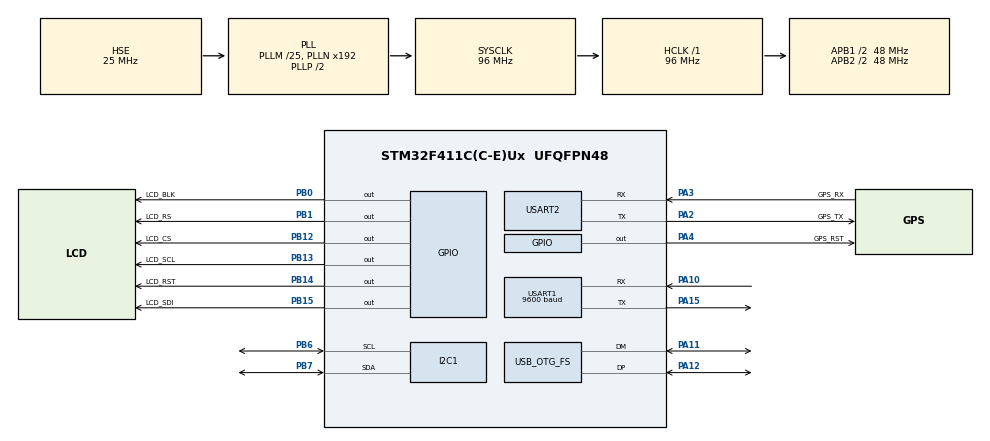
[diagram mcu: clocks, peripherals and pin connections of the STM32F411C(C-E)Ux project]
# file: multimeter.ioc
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Dma.I2C1_RX.0.Direction=DMA_PERIPH_TO_MEMORY
Dma.I2C1_RX.0.FIFOMode=DMA_FIFOMODE_DISABLE
Dma.I2C1_RX.0.Instance=DMA1_Stream0
Dma.I2C1_RX.0.MemDataAlignment=DMA_MDATAALIGN_BYTE
Dma.I2C1_RX.0.MemInc=DMA_MINC_ENABLE
Dma.I2C1_RX.0.Mode=DMA_NORMAL
Dma.I2C1_RX.0.PeriphDataAlignment=DMA_PDATAALIGN_BYTE
Dma.I2C1_RX.0.PeriphInc=DMA_PINC_DISABLE
Dma.I2C1_RX.0.Priority=DMA_PRIORITY_LOW
Dma.I2C1_TX.1.Direction=DMA_MEMORY_TO_PERIPH
Dma.I2C1_TX.1.FIFOMode=DMA_FIFOMODE_DISABLE
Dma.I2C1_TX.1.Instance=DMA1_Stream1
Dma.I2C1_TX.1.MemDataAlignment=DMA_MDATAALIGN_BYTE
Dma.I2C1_TX.1.MemInc=DMA_MINC_ENABLE
Dma.I2C1_TX.1.Mode=DMA_NORMAL
Dma.I2C1_TX.1.PeriphDataAlignment=DMA_PDATAALIGN_BYTE
Dma.I2C1_TX.1.PeriphInc=DMA_PINC_DISABLE
Dma.I2C1_TX.1.Priority=DMA_PRIORITY_LOW
Dma.Request0=I2C1_RX
Dma.Request1=I2C1_TX
Mcu.Family=STM32F4
Mcu.Name=STM32F411C(C-E)Ux
Mcu.Package=UFQFPN48
NVIC.DMA1_Stream0_IRQn=true\:0\:0\:false\:false\:true\:false\:true\:true
NVIC.DMA1_Stream1_IRQn=true\:0\:0\:false\:false\:true\:false\:true\:true
NVIC.I2C1_ER_IRQn=true\:0\:0\:false\:false\:true\:true\:true\:true
NVIC.I2C1_EV_IRQn=true\:0\:0\:false\:false\:true\:true\:true\:true
NVIC.OTG_FS_IRQn=true\:0\:0\:false\:false\:true\:false\:true\:true
NVIC.PriorityGroup=NVIC_PRIORITYGROUP_4
NVIC.USART1_IRQn=true\:0\:0\:true\:false\:true\:true\:true\:true
PA10.GPIO_PuPd=GPIO_PULLUP
PA10.Mode=Asynchronous
PA10.Signal=USART1_RX
PA11.Mode=Device_Only
PA11.Signal=USB_OTG_FS_DM
PA12.Mode=Device_Only
PA12.Signal=USB_OTG_FS_DP
PA13.Mode=Serial_Wire
PA13.Signal=SYS_JTMS-SWDIO
PA14.Mode=Serial_Wire
PA14.Signal=SYS_JTCK-SWCLK
PA15.GPIO_PuPd=GPIO_PULLUP
PA15.Mode=Asynchronous
PA15.Signal=USART1_TX
PA2.GPIO_Label=GPS_TX
PA2.Mode=Asynchronous
PA2.Signal=USART2_TX
PA3.GPIO_Label=GPS_RX
PA3.Mode=Asynchronous
PA3.Signal=USART2_RX
PA4.GPIO_Label=GPS_RST
PA4.Signal=GPIO_Output
PB0.GPIO_Label=LCD_BLK
PB0.GPIO_PuPd=GPIO_PULLUP
PB0.Signal=GPIO_Output
PB1.GPIO_Label=LCD_RS
PB1.GPIO_PuPd=GPIO_PULLUP
PB1.Signal=GPIO_Output
PB12.GPIO_Label=LCD_CS
PB12.GPIO_PuPd=GPIO_PULLUP
PB12.Signal=GPIO_Output
PB13.GPIO_Label=LCD_SCL
PB13.GPIO_PuPd=GPIO_PULLUP
PB13.Signal=GPIO_Output
PB14.GPIO_Label=LCD_RST
PB14.GPIO_PuPd=GPIO_PULLUP
PB14.Signal=GPIO_Output
PB15.GPIO_Label=LCD_SDI
PB15.GPIO_PuPd=GPIO_PULLUP
PB15.Signal=GPIO_Output
PB6.Mode=I2C
PB6.Signal=I2C1_SCL
PB7.Mode=I2C
PB7.Signal=I2C1_SDA
PC14-OSC32_IN.Mode=LSE-External-Oscillator
PC14-OSC32_IN.Signal=RCC_OSC32_IN
PC15-OSC32_OUT.Mode=LSE-External-Oscillator
PC15-OSC32_OUT.Signal=RCC_OSC32_OUT
PH0\ -\ OSC_IN.Mode=HSE-External-Oscillator
PH0\ -\ OSC_IN.Signal=RCC_OSC_IN
PH1\ -\ OSC_OUT.Mode=HSE-External-Oscillator
PH1\ -\ OSC_OUT.Signal=RCC_OSC_OUT
ProjectManager.HeapSize=0x200
ProjectManager.StackSize=0x400
ProjectManager.TargetToolchain=STM32CubeIDE
RCC.48MHZClocksFreq_Value=48000000
RCC.AHBFreq_Value=96000000
RCC.APB1CLKDivider=RCC_HCLK_DIV2
RCC.APB1Freq_Value=48000000
RCC.APB1TimFreq_Value=96000000
RCC.APB2CLKDivider=RCC_HCLK_DIV2
RCC.APB2Freq_Value=48000000
RCC.APB2TimFreq_Value=96000000
RCC.CortexFreq_Value=96000000
RCC.HCLKFreq_Value=96000000
RCC.HSE_VALUE=25000000
RCC.HSI_VALUE=16000000
RCC.PLLM=25
RCC.SYSCLKFreq_VALUE=96000000
RCC.SYSCLKSource=RCC_SYSCLKSOURCE_PLLCLK
RCC.VCOOutputFreq_Value=192000000
TIM5.Prescaler=95
USART1.BaudRate=9600
USART1.VirtualMode=VM_ASYNC
USART2.VirtualMode=VM_ASYNC
USB_DEVICE.CLASS_NAME_FS=CDC
USB_DEVICE.VirtualMode=Cdc
USB_DEVICE.VirtualModeFS=Cdc_FS
USB_OTG_FS.VirtualMode=Device_Only
VP_TIM5_VS_ClockSourceINT.Mode=Internal
VP_USB_DEVICE_VS_USB_DEVICE_CDC_FS.Mode=CDC_FS
board=custom

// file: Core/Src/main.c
/* USER CODE BEGIN Header */
/**
  ******************************************************************************
  * @file           : main.c
  * @brief          : Main program body
  ******************************************************************************
  * @attention
  *
  * Copyright (c) 2023 STMicroelectronics.
  * All rights reserved.
  *
  * This software is licensed under terms that can be found in the LICENSE file
  * in the root directory of this software component.
  * If no LICENSE file comes with this software, it is provided AS-IS.
  *
  ******************************************************************************
  */
/* USER CODE END Header */
#include "main.h"
#include "usb_device.h"

/* USER CODE BEGIN Includes */
#include "projectMain.h"
/* USER CODE END Includes */

void SystemClock_Config(void);
static void MX_GPIO_Init(void);
static void MX_DMA_Init(void);
static void MX_USART1_UART_Init(void);
static void MX_USART2_UART_Init(void);
static void MX_TIM5_Init(void);
static void MX_I2C1_Init(void);

int main(void)
{

  /* MCU Configuration--------------------------------------------------------*/

  /* Reset of all peripherals, Initializes the Flash interface and the Systick. */
  HAL_Init();

  /* Configure the system clock */
  SystemClock_Config();

  /* Initialize all configured peripherals */
  MX_GPIO_Init();
  MX_DMA_Init();
  MX_USART1_UART_Init();
  MX_USART2_UART_Init();
  MX_USB_DEVICE_Init();
  MX_TIM5_Init();
  MX_I2C1_Init();
  /* USER CODE BEGIN 2 */

  projectMain();

    ////////////////////////////////////////
    // The code should never reach here
    ////////////////////////////////////////

  /* USER CODE END 2 */

  /* Infinite loop */
  while (1)
  {

  }
}

void SystemClock_Config(void)
{
  RCC_OscInitTypeDef RCC_OscInitStruct = {0};
  RCC_ClkInitTypeDef RCC_ClkInitStruct = {0};

  /** Configure the main internal regulator output voltage
  */
  __HAL_RCC_PWR_CLK_ENABLE();
  __HAL_PWR_VOLTAGESCALING_CONFIG(PWR_REGULATOR_VOLTAGE_SCALE1);

  /** Initializes the RCC Oscillators according to the specified parameters
  * in the RCC_OscInitTypeDef structure.
  */
  RCC_OscInitStruct.OscillatorType = RCC_OSCILLATORTYPE_HSE;
  RCC_OscInitStruct.HSEState = RCC_HSE_ON;
  RCC_OscInitStruct.PLL.PLLState = RCC_PLL_ON;
  RCC_OscInitStruct.PLL.PLLSource = RCC_PLLSOURCE_HSE;
  RCC_OscInitStruct.PLL.PLLM = 25;
  RCC_OscInitStruct.PLL.PLLN = 192;
  RCC_OscInitStruct.PLL.PLLP = RCC_PLLP_DIV2;
  RCC_OscInitStruct.PLL.PLLQ = 4;
  if (HAL_RCC_OscConfig(&RCC_OscInitStruct) != HAL_OK)
  {
    Error_Handler();
  }

  /** Initializes the CPU, AHB and APB buses clocks
  */
  RCC_ClkInitStruct.ClockType = RCC_CLOCKTYPE_HCLK|RCC_CLOCKTYPE_SYSCLK
                              |RCC_CLOCKTYPE_PCLK1|RCC_CLOCKTYPE_PCLK2;
  RCC_ClkInitStruct.SYSCLKSource = RCC_SYSCLKSOURCE_PLLCLK;
  RCC_ClkInitStruct.AHBCLKDivider = RCC_SYSCLK_DIV1;
  RCC_ClkInitStruct.APB1CLKDivider = RCC_HCLK_DIV2;
  RCC_ClkInitStruct.APB2CLKDivider = RCC_HCLK_DIV2;

  if (HAL_RCC_ClockConfig(&RCC_ClkInitStruct, FLASH_LATENCY_3) != HAL_OK)
  {
    Error_Handler();
  }
}

static void MX_I2C1_Init(void)
{

  LL_I2C_InitTypeDef I2C_InitStruct = {0};

  LL_GPIO_InitTypeDef GPIO_InitStruct = {0};

  LL_AHB1_GRP1_EnableClock(LL_AHB1_GRP1_PERIPH_GPIOB);
  /**I2C1 GPIO Configuration
  PB6   ------> I2C1_SCL
  PB7   ------> I2C1_SDA
  */
  GPIO_InitStruct.Pin = LL_GPIO_PIN_6|LL_GPIO_PIN_7;
  GPIO_InitStruct.Mode = LL_GPIO_MODE_ALTERNATE;
  GPIO_InitStruct.Speed = LL_GPIO_SPEED_FREQ_VERY_HIGH;
  GPIO_InitStruct.OutputType = LL_GPIO_OUTPUT_OPENDRAIN;
  GPIO_InitStruct.Pull = LL_GPIO_PULL_NO;
  GPIO_InitStruct.Alternate = LL_GPIO_AF_4;
  LL_GPIO_Init(GPIOB, &GPIO_InitStruct);

  /* Peripheral clock enable */
  LL_APB1_GRP1_EnableClock(LL_APB1_GRP1_PERIPH_I2C1);

  /* I2C1 DMA Init */

  /* I2C1_RX Init */
  LL_DMA_SetChannelSelection(DMA1, LL_DMA_STREAM_0, LL_DMA_CHANNEL_1);

  LL_DMA_SetDataTransferDirection(DMA1, LL_DMA_STREAM_0, LL_DMA_DIRECTION_PERIPH_TO_MEMORY);

  LL_DMA_SetStreamPriorityLevel(DMA1, LL_DMA_STREAM_0, LL_DMA_PRIORITY_LOW);

  LL_DMA_SetMode(DMA1, LL_DMA_STREAM_0, LL_DMA_MODE_NORMAL);

  LL_DMA_SetPeriphIncMode(DMA1, LL_DMA_STREAM_0, LL_DMA_PERIPH_NOINCREMENT);

  LL_DMA_SetMemoryIncMode(DMA1, LL_DMA_STREAM_0, LL_DMA_MEMORY_INCREMENT);

  LL_DMA_SetPeriphSize(DMA1, LL_DMA_STREAM_0, LL_DMA_PDATAALIGN_BYTE);

  LL_DMA_SetMemorySize(DMA1, LL_DMA_STREAM_0, LL_DMA_MDATAALIGN_BYTE);

  LL_DMA_DisableFifoMode(DMA1, LL_DMA_STREAM_0);

  /* I2C1_TX Init */
  LL_DMA_SetChannelSelection(DMA1, LL_DMA_STREAM_1, LL_DMA_CHANNEL_0);

  LL_DMA_SetDataTransferDirection(DMA1, LL_DMA_STREAM_1, LL_DMA_DIRECTION_MEMORY_TO_PERIPH);

  LL_DMA_SetStreamPriorityLevel(DMA1, LL_DMA_STREAM_1, LL_DMA_PRIORITY_LOW);

  LL_DMA_SetMode(DMA1, LL_DMA_STREAM_1, LL_DMA_MODE_NORMAL);

  LL_DMA_SetPeriphIncMode(DMA1, LL_DMA_STREAM_1, LL_DMA_PERIPH_NOINCREMENT);

  LL_DMA_SetMemoryIncMode(DMA1, LL_DMA_STREAM_1, LL_DMA_MEMORY_INCREMENT);

  LL_DMA_SetPeriphSize(DMA1, LL_DMA_STREAM_1, LL_DMA_PDATAALIGN_BYTE);

  LL_DMA_SetMemorySize(DMA1, LL_DMA_STREAM_1, LL_DMA_MDATAALIGN_BYTE);

  LL_DMA_DisableFifoMode(DMA1, LL_DMA_STREAM_1);

  /* I2C1 interrupt Init */
  NVIC_SetPriority(I2C1_EV_IRQn, NVIC_EncodePriority(NVIC_GetPriorityGrouping(),0, 0));
  NVIC_EnableIRQ(I2C1_EV_IRQn);
  NVIC_SetPriority(I2C1_ER_IRQn, NVIC_EncodePriority(NVIC_GetPriorityGrouping(),0, 0));
  NVIC_EnableIRQ(I2C1_ER_IRQn);

  /** I2C Initialization
  */
  LL_I2C_DisableOwnAddress2(I2C1);
  LL_I2C_DisableGeneralCall(I2C1);
  LL_I2C_EnableClockStretching(I2C1);
  I2C_InitStruct.PeripheralMode = LL_I2C_MODE_I2C;
  I2C_InitStruct.ClockSpeed = 100000;
  I2C_InitStruct.DutyCycle = LL_I2C_DUTYCYCLE_2;
  I2C_InitStruct.OwnAddress1 = 0;
  I2C_InitStruct.TypeAcknowledge = LL_I2C_ACK;
  I2C_InitStruct.OwnAddrSize = LL_I2C_OWNADDRESS1_7BIT;
  LL_I2C_Init(I2C1, &I2C_InitStruct);
  LL_I2C_SetOwnAddress2(I2C1, 0);

}

static void MX_TIM5_Init(void)
{

  LL_TIM_InitTypeDef TIM_InitStruct = {0};

  /* Peripheral clock enable */
  LL_APB1_GRP1_EnableClock(LL_APB1_GRP1_PERIPH_TIM5);

  TIM_InitStruct.Prescaler = 95;
  TIM_InitStruct.CounterMode = LL_TIM_COUNTERMODE_UP;
  TIM_InitStruct.Autoreload = 4294967295;
  TIM_InitStruct.ClockDivision = LL_TIM_CLOCKDIVISION_DIV1;
  LL_TIM_Init(TIM5, &TIM_InitStruct);
  LL_TIM_DisableARRPreload(TIM5);
  LL_TIM_SetClockSource(TIM5, LL_TIM_CLOCKSOURCE_INTERNAL);
  LL_TIM_SetTriggerOutput(TIM5, LL_TIM_TRGO_RESET);
  LL_TIM_DisableMasterSlaveMode(TIM5);

}

static void MX_USART1_UART_Init(void)
{

  LL_USART_InitTypeDef USART_InitStruct = {0};

  LL_GPIO_InitTypeDef GPIO_InitStruct = {0};

  /* Peripheral clock enable */
  LL_APB2_GRP1_EnableClock(LL_APB2_GRP1_PERIPH_USART1);

  LL_AHB1_GRP1_EnableClock(LL_AHB1_GRP1_PERIPH_GPIOA);
  /**USART1 GPIO Configuration
  PA10   ------> USART1_RX
  PA15   ------> USART1_TX
  */
  GPIO_InitStruct.Pin = LL_GPIO_PIN_10|LL_GPIO_PIN_15;
  GPIO_InitStruct.Mode = LL_GPIO_MODE_ALTERNATE;
  GPIO_InitStruct.Speed = LL_GPIO_SPEED_FREQ_VERY_HIGH;
  GPIO_InitStruct.OutputType = LL_GPIO_OUTPUT_PUSHPULL;
  GPIO_InitStruct.Pull = LL_GPIO_PULL_UP;
  GPIO_InitStruct.Alternate = LL_GPIO_AF_7;
  LL_GPIO_Init(GPIOA, &GPIO_InitStruct);

  /* USART1 interrupt Init */
  NVIC_SetPriority(USART1_IRQn, NVIC_EncodePriority(NVIC_GetPriorityGrouping(),0, 0));
  NVIC_EnableIRQ(USART1_IRQn);

  USART_InitStruct.BaudRate = 9600;
  USART_InitStruct.DataWidth = LL_USART_DATAWIDTH_8B;
  USART_InitStruct.StopBits = LL_USART_STOPBITS_1;
  USART_InitStruct.Parity = LL_USART_PARITY_NONE;
  USART_InitStruct.TransferDirection = LL_USART_DIRECTION_TX_RX;
  USART_InitStruct.HardwareFlowControl = LL_USART_HWCONTROL_NONE;
  USART_InitStruct.OverSampling = LL_USART_OVERSAMPLING_16;
  LL_USART_Init(USART1, &USART_InitStruct);
  LL_USART_ConfigAsyncMode(USART1);
  LL_USART_Enable(USART1);

}

static void MX_USART2_UART_Init(void)
{

  LL_USART_InitTypeDef USART_InitStruct = {0};

  LL_GPIO_InitTypeDef GPIO_InitStruct = {0};

  /* Peripheral clock enable */
  LL_APB1_GRP1_EnableClock(LL_APB1_GRP1_PERIPH_USART2);

  LL_AHB1_GRP1_EnableClock(LL_AHB1_GRP1_PERIPH_GPIOA);
  /**USART2 GPIO Configuration
  PA2   ------> USART2_TX
  PA3   ------> USART2_RX
  */
  GPIO_InitStruct.Pin = GPS_TX_Pin|GPS_RX_Pin;
  GPIO_InitStruct.Mode = LL_GPIO_MODE_ALTERNATE;
  GPIO_InitStruct.Speed = LL_GPIO_SPEED_FREQ_VERY_HIGH;
  GPIO_InitStruct.OutputType = LL_GPIO_OUTPUT_PUSHPULL;
  GPIO_InitStruct.Pull = LL_GPIO_PULL_NO;
  GPIO_InitStruct.Alternate = LL_GPIO_AF_7;
  LL_GPIO_Init(GPIOA, &GPIO_InitStruct);

  USART_InitStruct.BaudRate = 115200;
  USART_InitStruct.DataWidth = LL_USART_DATAWIDTH_8B;
  USART_InitStruct.StopBits = LL_USART_STOPBITS_1;
  USART_InitStruct.Parity = LL_USART_PARITY_NONE;
  USART_InitStruct.TransferDirection = LL_USART_DIRECTION_TX_RX;
  USART_InitStruct.HardwareFlowControl = LL_USART_HWCONTROL_NONE;
  USART_InitStruct.OverSampling = LL_USART_OVERSAMPLING_16;
  LL_USART_Init(USART2, &USART_InitStruct);
  LL_USART_ConfigAsyncMode(USART2);
  LL_USART_Enable(USART2);

}

static void MX_DMA_Init(void)
{

  /* DMA controller clock enable */
  __HAL_RCC_DMA1_CLK_ENABLE();

  /* DMA interrupt init */
  /* DMA1_Stream0_IRQn interrupt configuration */
  NVIC_SetPriority(DMA1_Stream0_IRQn, NVIC_EncodePriority(NVIC_GetPriorityGrouping(),0, 0));
  NVIC_EnableIRQ(DMA1_Stream0_IRQn);
  /* DMA1_Stream1_IRQn interrupt configuration */
  NVIC_SetPriority(DMA1_Stream1_IRQn, NVIC_EncodePriority(NVIC_GetPriorityGrouping(),0, 0));
  NVIC_EnableIRQ(DMA1_Stream1_IRQn);

}

static void MX_GPIO_Init(void)
{
  LL_GPIO_InitTypeDef GPIO_InitStruct = {0};

  /* GPIO Ports Clock Enable */
  LL_AHB1_GRP1_EnableClock(LL_AHB1_GRP1_PERIPH_GPIOC);
  LL_AHB1_GRP1_EnableClock(LL_AHB1_GRP1_PERIPH_GPIOH);
  LL_AHB1_GRP1_EnableClock(LL_AHB1_GRP1_PERIPH_GPIOA);
  LL_AHB1_GRP1_EnableClock(LL_AHB1_GRP1_PERIPH_GPIOB);

  /**/
  LL_GPIO_ResetOutputPin(GPS_RST_GPIO_Port, GPS_RST_Pin);

  /**/
  LL_GPIO_ResetOutputPin(GPIOB, LCD_BLK_Pin|LCD_RS_Pin|LCD_CS_Pin|LCD_SCL_Pin
                          |LCD_RST_Pin|LCD_SDI_Pin);

  /**/
  GPIO_InitStruct.Pin = GPS_RST_Pin;
  GPIO_InitStruct.Mode = LL_GPIO_MODE_OUTPUT;
  GPIO_InitStruct.Speed = LL_GPIO_SPEED_FREQ_LOW;
  GPIO_InitStruct.OutputType = LL_GPIO_OUTPUT_PUSHPULL;
  GPIO_InitStruct.Pull = LL_GPIO_PULL_NO;
  LL_GPIO_Init(GPS_RST_GPIO_Port, &GPIO_InitStruct);

  /**/
  GPIO_InitStruct.Pin = LCD_BLK_Pin|LCD_RS_Pin|LCD_CS_Pin|LCD_SCL_Pin
                          |LCD_RST_Pin|LCD_SDI_Pin;
  GPIO_InitStruct.Mode = LL_GPIO_MODE_OUTPUT;
  GPIO_InitStruct.Speed = LL_GPIO_SPEED_FREQ_LOW;
  GPIO_InitStruct.OutputType = LL_GPIO_OUTPUT_PUSHPULL;
  GPIO_InitStruct.Pull = LL_GPIO_PULL_UP;
  LL_GPIO_Init(GPIOB, &GPIO_InitStruct);

}

void Error_Handler(void)
{
  __disable_irq();
  while (1)
  {
  }
}
